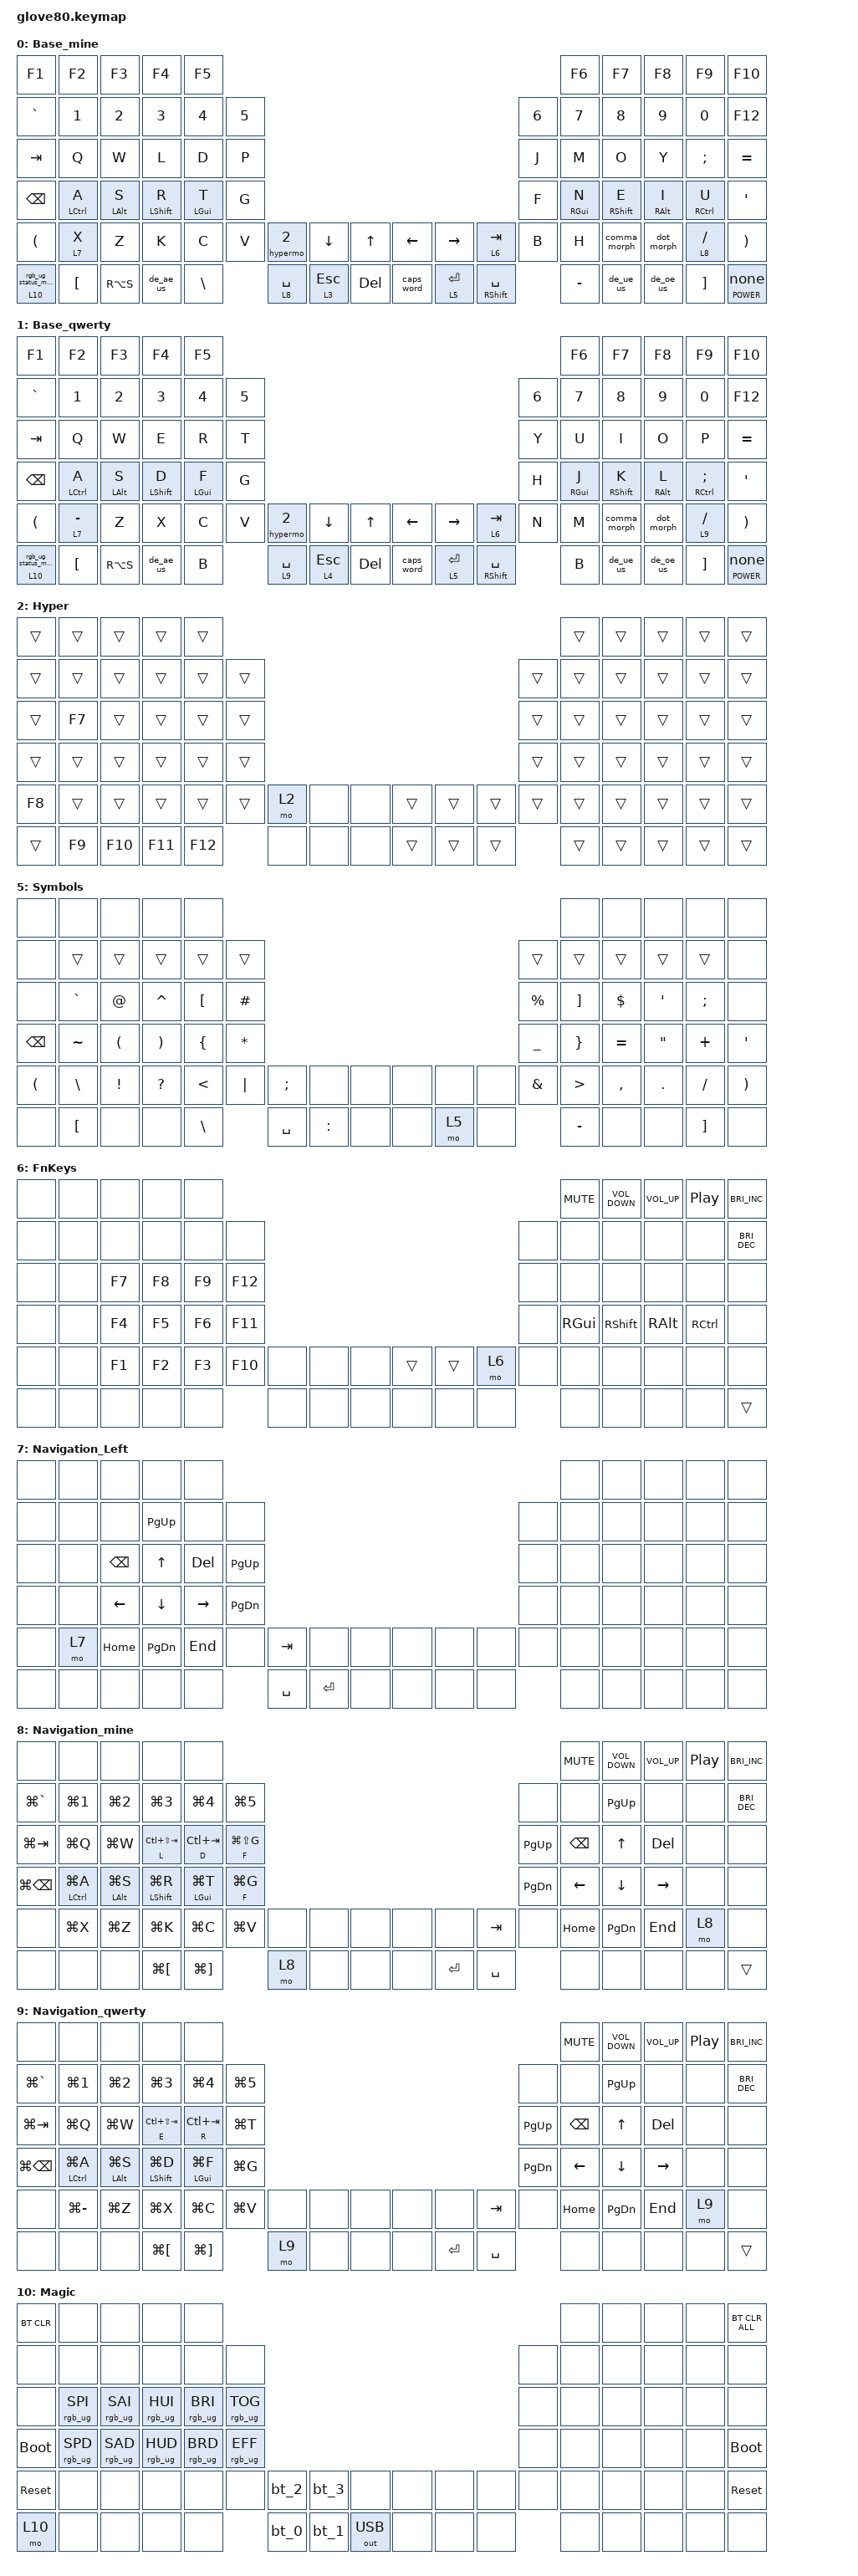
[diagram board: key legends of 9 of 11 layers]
/*
 * Copyright (c) 2020 The ZMK Contributors
 *
 * SPDX-License-Identifier: MIT
 */

#include <behaviors.dtsi>
#include <dt-bindings/zmk/bt.h>
#include <dt-bindings/zmk/keys.h>
#include <dt-bindings/zmk/outputs.h>
#include <dt-bindings/zmk/rgb.h>

&lt {
    quick-tap-ms = <200>;
    flavor = "balanced";
};

&mt {
    flavor = "balanced";
    quick-tap-ms = <200>;
};

&sk {
    quick-release;
    release-after-ms = <500>;
};

&sl {
    ignore-modifiers;
    release-after-ms = <500>;
};

/ {
    behaviors {
        magic: magic {
            compatible = "zmk,behavior-hold-tap";
            label = "MAGIC";
            #binding-cells = <2>;
            flavor = "tap-preferred";
            tapping-term-ms = <200>;
            bindings = <&mo>, <&rgb_ug_status_macro>;
        };

        hml: hml {
            compatible = "zmk,behavior-hold-tap";
            label = "HML";
            bindings = <&kp>, <&kp>;

            #binding-cells = <2>;
            tapping-term-ms = <300>;
            quick-tap-ms = <200>;
            require-prior-idle-ms = <100>;
            flavor = "balanced";
            hold-trigger-key-positions = <5 6 7 8 9 16 17 18 19 20 21 28 29 30 31 32 33 40 41 42 43 44 45 57 58 59 60 61 62 63 73 74 75 76 77 78 79 56 72 55 52 53 54 70 71 69>;
            hold-trigger-on-release;
        };

        hmr: hmr {
            compatible = "zmk,behavior-hold-tap";
            label = "HMR";
            bindings = <&kp>, <&kp>;

            #binding-cells = <2>;
            tapping-term-ms = <300>;
            quick-tap-ms = <200>;
            require-prior-idle-ms = <100>;
            flavor = "balanced";
            hold-trigger-key-positions = <57 73 74 56 72 55 52 53 54 70 71 69 0 1 2 3 4 10 11 12 13 14 15 22 23 24 25 26 27 34 35 36 37 38 39 46 47 48 49 50 51 52 64 65 66 67 68 69 70>;
            hold-trigger-on-release;
        };

        comma_morph: comma_morph {
            compatible = "zmk,behavior-mod-morph";
            label = "COMMA_MORPH";
            bindings = <&kp COMMA>, <&comma_shift>;

            #binding-cells = <0>;
            mods = <(MOD_LSFT|MOD_RSFT)>;
        };

        dot_morph: dot_morph {
            compatible = "zmk,behavior-mod-morph";
            label = "DOT_MORPH";
            bindings = <&kp DOT>, <&dot_shift>;

            #binding-cells = <0>;
            mods = <(MOD_LSFT|MOD_RSFT)>;
        };

        cmdhold: cmdhold {
            compatible = "zmk,behavior-hold-tap";
            label = "CMDHOLD";
            bindings = <&cmdtap>, <&kp>;

            #binding-cells = <2>;
            flavor = "tap-preferred";
            tapping-term-ms = <200>;
        };

        cmdsfthold: cmdsfthold {
            compatible = "zmk,behavior-hold-tap";
            label = "CMDSFTHOLD";
            bindings = <&cmdsfttap>, <&kp>;

            #binding-cells = <2>;
            tapping-term-ms = <200>;
            flavor = "tap-preferred";
        };

        hypermo_kp: hypermo_kp {
            compatible = "zmk,behavior-hold-tap";
            label = "HYPERMO_KP";
            bindings = <&hypermo>, <&kp>;

            #binding-cells = <2>;
            tapping-term-ms = <200>;
            flavor = "balanced";
            quick-tap-ms = <200>;
        };

        hypermo_sk: hypermo_sk {
            compatible = "zmk,behavior-hold-tap";
            label = "HYPERMO_SK";
            bindings = <&hypermo>, <&sk>;

            #binding-cells = <2>;
            tapping-term-ms = <200>;
            flavor = "balanced";
        };

        lpar_lt: lpar_lt {
            compatible = "zmk,behavior-mod-morph";
            label = "LPAR_LT";
            bindings = <&kp LEFT_PARENTHESIS>, <&kp LESS_THAN>;

            #binding-cells = <0>;
            mods = <(MOD_LSFT|MOD_RSFT)>;
        };

        rpar_gt: rpar_gt {
            compatible = "zmk,behavior-mod-morph";
            label = "RPAR_GT";
            bindings = <&kp RIGHT_PARENTHESIS>, <&kp GREATER_THAN>;

            #binding-cells = <0>;
            mods = <(MOD_LSFT|MOD_RSFT)>;
        };

        ltw: ltw {
            compatible = "zmk,behavior-hold-tap";
            label = "LTW";
            bindings = <&mo>, <&kp>;

            #binding-cells = <2>;
            tapping-term-ms = <200>;
            flavor = "balanced";
        };

        htw: htw {
            compatible = "zmk,behavior-hold-tap";
            label = "HTW";
            bindings = <&tap>, <&kp>;

            #binding-cells = <2>;
            tapping-term-ms = <200>;
            flavor = "balanced";
        };

        de_ae_us: de_ae_us {
            compatible = "zmk,behavior-mod-morph";
            label = "DE_AE_US";
            bindings = <&de_ae_lower_us>, <&de_ae_upper_us>;

            #binding-cells = <0>;
            mods = <(MOD_RSFT|MOD_LSFT)>;
        };

        de_ue_us: de_ue_us {
            compatible = "zmk,behavior-mod-morph";
            label = "DE_UE_US";
            bindings = <&de_ue_lower_us>, <&de_ue_upper_us>;

            #binding-cells = <0>;
            mods = <(MOD_RSFT|MOD_LSFT)>;
        };

        de_oe_us: de_oe_us {
            compatible = "zmk,behavior-mod-morph";
            label = "DE_OE_US";
            bindings = <&de_oe_lower_us>, <&de_oe_upper_us>;

            #binding-cells = <0>;
            mods = <(MOD_RSFT|MOD_LSFT)>;
        };

        ht_sk_kp: ht_sk_kp {
            compatible = "zmk,behavior-hold-tap";
            label = "HT_SK_KP";
            bindings = <&sk>, <&kp>;

            #binding-cells = <2>;
            tapping-term-ms = <300>;
            flavor = "hold-preferred";
        };

        long_hold: long_hold {
            compatible = "zmk,behavior-hold-tap";
            label = "LONG_HOLD";
            bindings = <&kp>, <&none>;

            #binding-cells = <2>;
            tapping-term-ms = <2000>;
            flavor = "tap-preferred";
        };

        comma_shift: comma_shift {
            compatible = "zmk,behavior-mod-morph";
            label = "COMMA_SHIFT";
            bindings = <&kp SEMICOLON>, <&kp LESS_THAN>;

            #binding-cells = <0>;
            mods = <(MOD_LCTL|MOD_LGUI|MOD_LALT|MOD_RCTL|MOD_RALT|MOD_RGUI)>;
            keep-mods = <(MOD_LCTL|MOD_LALT|MOD_LGUI|MOD_RCTL|MOD_RALT|MOD_RGUI)>;
        };

        dot_shift: dot_shift {
            compatible = "zmk,behavior-mod-morph";
            label = "DOT_SHIFT";
            bindings = <&kp COLON>, <&kp GREATER_THAN>;

            #binding-cells = <0>;
            mods = <(MOD_LCTL|MOD_LGUI|MOD_LALT|MOD_RCTL|MOD_RALT|MOD_RGUI)>;
            keep-mods = <(MOD_LCTL|MOD_LALT|MOD_LGUI|MOD_RCTL|MOD_RALT|MOD_RGUI)>;
        };
    };

    macros {
        rgb_ug_status_macro: rgb_ug_status_macro_0 {
            label = "RGB_UG_STATUS";
            compatible = "zmk,behavior-macro";
            #binding-cells = <0>;
            bindings = <&rgb_ug RGB_STATUS>;
        };

        bt_0: bt_profile_macro_0 {
            label = "BT_0";
            compatible = "zmk,behavior-macro";
            #binding-cells = <0>;
            bindings = <&out OUT_BLE &bt BT_SEL 0>;
        };

        bt_1: bt_profile_macro_1 {
            label = "BT_1";
            compatible = "zmk,behavior-macro";
            #binding-cells = <0>;
            bindings = <&out OUT_BLE &bt BT_SEL 1>;
        };

        bt_2: bt_profile_macro_2 {
            label = "BT_2";
            compatible = "zmk,behavior-macro";
            #binding-cells = <0>;
            bindings = <&out OUT_BLE &bt BT_SEL 2>;
        };

        bt_3: bt_profile_macro_3 {
            label = "BT_3";
            compatible = "zmk,behavior-macro";
            #binding-cells = <0>;
            bindings = <&out OUT_BLE &bt BT_SEL 3>;
        };

        cmdtap: cmdtap {
            compatible = "zmk,behavior-macro-one-param";
            #binding-cells = <1>;
            bindings =
                <&macro_press>,
                <&kp LGUI>,
                <&macro_tap>,
                <&macro_param_1to1 &kp MACRO_PLACEHOLDER>,
                <&macro_release>,
                <&kp LGUI>;

            label = "CMDTAP";
        };

        cmdsfttap: cmdsfttap {
            compatible = "zmk,behavior-macro-one-param";
            #binding-cells = <1>;
            bindings =
                <&macro_press>,
                <&kp LGUI &kp LSHFT>,
                <&macro_tap>,
                <&macro_param_1to1 &kp MACRO_PLACEHOLDER>,
                <&macro_release>,
                <&kp LSHFT &kp LGUI>;

            label = "CMDSFTTAP";
        };

        hypermo: hypermo {
            compatible = "zmk,behavior-macro-one-param";
            #binding-cells = <1>;
            bindings =
                <&macro_press>,
                <&kp LGUI &kp LALT &kp LCTRL &kp LSHFT &macro_param_1to1 &mo MACRO_PLACEHOLDER>,
                <&macro_pause_for_release>,
                <&macro_release>,
                <&macro_param_1to1 &mo MACRO_PLACEHOLDER &kp LSHFT &kp LCTRL &kp LALT &kp LGUI>;

            label = "HYPERMO";
        };

        tap: tap {
            compatible = "zmk,behavior-macro-one-param";
            #binding-cells = <1>;
            bindings = <&macro_param_1to1 &kp MACRO_PLACEHOLDER>;
            label = "TAP";
        };

        de_ae_lower_us: de_ae_lower_us {
            compatible = "zmk,behavior-macro";
            #binding-cells = <0>;
            bindings = <&kp LA(U) &kp A>;
            label = "DE_AE_LOWER_US";
        };

        de_ae_upper_us: de_ae_upper_us {
            compatible = "zmk,behavior-macro";
            #binding-cells = <0>;
            bindings = <&kp LA(U) &kp LS(A)>;
            label = "DE_AE_UPPER_US";
        };

        de_ue_lower_us: de_ue_lower_us {
            compatible = "zmk,behavior-macro";
            #binding-cells = <0>;
            bindings = <&kp LA(U) &kp U>;
            label = "DE_UE_LOWER_US";
        };

        de_ue_upper_us: de_ue_upper_us {
            compatible = "zmk,behavior-macro";
            #binding-cells = <0>;
            bindings = <&kp LA(U) &kp LS(U)>;
            label = "DE_UE_UPPER_US";
        };

        de_oe_lower_us: de_oe_lower_us {
            compatible = "zmk,behavior-macro";
            #binding-cells = <0>;
            bindings = <&kp LA(U) &kp O>;
            label = "DE_OE_LOWER_US";
        };

        de_oe_upper_us: de_oe_upper_us {
            compatible = "zmk,behavior-macro";
            #binding-cells = <0>;
            bindings = <&kp LA(U) &kp LS(O)>;
            label = "DE_OE_UPPER_US";
        };
    };

    combos {
        compatible = "zmk,combos";

        combo_escape {
            bindings = <&kp ESCAPE>;
            key-positions = <37 36>;
            layers = <0 1>;
            require-prior-idle-ms = <100>;
            timeout-ms = <40>;
        };

        combo_return {
            bindings = <&kp RETURN>;
            key-positions = <42 43>;
            layers = <0 1>;
            timeout-ms = <40>;
            require-prior-idle-ms = <100>;
        };

        combo_minus {
            bindings = <&kp MINUS>;
            key-positions = <30 31>;
            layers = <0 1>;
            timeout-ms = <40>;
        };

        combo_exclamation {
            bindings = <&kp EXCLAMATION>;
            key-positions = <49 48>;
            layers = <0 1>;
            timeout-ms = <40>;
        };

        combo_question {
            bindings = <&kp QUESTION>;
            key-positions = <60 61>;
            layers = <0 1>;
            timeout-ms = <40>;
        };

        combo_equal {
            bindings = <&kp EQUAL>;
            key-positions = <24 25>;
            layers = <0 1>;
            timeout-ms = <40>;
        };
    };

    keymap {
        compatible = "zmk,keymap";

        Base_mine {
            // ---------------------------------------------------------------------------------------------------------------------------------
            // |  F1   |  F2 |  F3 |  F4  |  F5  |                                                               |  F6   |  F7   |  F8  |   F9  |  F10 |
            // |  =    |  1  |  2  |  3   |  4   |  5   |                                                 |  6   |   7   |   8   |  9   |   0   |   -  |
            // |  TAB  |  Q  |  W  |  E   |  R   |  T   |                                                 |  Y   |   U   |   I   |  O   |   P   |   \  |
            // |  ESC  |  A  |  S  |  D   |  F   |  G   |                                                 |  H   |   J   |   K   |  L   |   ;   |   '  |
            // |   `   |  Z  |  X  |  C   |  V   |  B   | LSHFT | LCTRL | LOWER | | LGUI  | RCTRL | RSHFT |  N   |   M   |   ,   |  .   |   /   | PGUP |
            // | MAGIC | HOME| END | LEFT | RIGHT|      | BSPC  | DEL   | LALT  | | RALT  | RET   | SPACE |      |  UP   | DOWN  |  [   |   ]   | PGDN |

            bindings = <
&kp F1                &kp F2            &kp F3       &kp F4        &kp F5                                                                                                                 &kp F6       &kp F7        &kp F8       &kp F9             &kp F10
&kp GRAVE             &kp N1            &kp N2       &kp N3        &kp N4         &kp N5                                                                                          &kp N6  &kp N7       &kp N8        &kp N9       &kp N0             &kp F12
&kp TAB               &kp Q             &kp W        &kp L         &kp D          &kp P                                                                                           &kp J   &kp M        &kp O         &kp Y        &kp SEMICOLON      &kp EQUAL
&kp BACKSPACE         &hml LCTRL A      &hml LALT S  &hml LSHFT R  &hml LGUI T    &kp G                                                                                           &kp F   &hmr RGUI N  &hmr RSHFT E  &hmr RALT I  &hmr RCTRL U       &kp SINGLE_QUOTE
&kp LEFT_PARENTHESIS  &lt 7 X           &kp Z        &kp K         &kp C          &kp V   &hypermo 2   &kp DOWN      &kp UP      &kp LEFT    &kp RIGHT     &lt 6 TAB              &kp B   &kp H        &comma_morph  &dot_morph   &lt 8 SLASH        &kp RIGHT_PARENTHESIS
&magic 10 0           &kp LEFT_BRACKET  &kp RA(S)    &de_ae_us     &kp BACKSLASH          &lt 8 SPACE  &lt 3 ESCAPE  &kp DELETE  &caps_word  &lt 5 RETURN  &ht_sk_kp RSHFT SPACE          &kp MINUS    &de_ue_us     &de_oe_us    &kp RIGHT_BRACKET  &long_hold C_POWER 0
            >;
        };

        Base_qwerty {
            bindings = <
&kp F1                &kp F2            &kp F3       &kp F4        &kp F5                                                                                                               &kp F6       &kp F7        &kp F8       &kp F9                &kp F10
&kp GRAVE             &kp N1            &kp N2       &kp N3        &kp N4       &kp N5                                                                                          &kp N6  &kp N7       &kp N8        &kp N9       &kp N0                &kp F12
&kp TAB               &kp Q             &kp W        &kp E         &kp R        &kp T                                                                                           &kp Y   &kp U        &kp I         &kp O        &kp P                 &kp EQUAL
&kp BACKSPACE         &hml LCTRL A      &hml LALT S  &hml LSHFT D  &hml LGUI F  &kp G                                                                                           &kp H   &hmr RGUI J  &hmr RSHFT K  &hmr RALT L  &hmr RCTRL SEMICOLON  &kp SINGLE_QUOTE
&kp LEFT_PARENTHESIS  &lt 7 MINUS       &kp Z        &kp X         &kp C        &kp V   &hypermo 2   &kp DOWN      &kp UP      &kp LEFT    &kp RIGHT     &lt 6 TAB              &kp N   &kp M        &comma_morph  &dot_morph   &lt 9 SLASH           &kp RIGHT_PARENTHESIS
&magic 10 0           &kp LEFT_BRACKET  &kp RA(S)    &de_ae_us     &kp B                &lt 9 SPACE  &lt 4 ESCAPE  &kp DELETE  &caps_word  &lt 5 RETURN  &ht_sk_kp RSHFT SPACE          &kp B        &de_ue_us     &de_oe_us    &kp RIGHT_BRACKET     &long_hold C_POWER 0
            >;
        };

        Hyper {
            bindings = <
&trans  &trans  &trans   &trans   &trans                                                                &trans  &trans  &trans  &trans  &trans
&trans  &trans  &trans   &trans   &trans   &trans                                               &trans  &trans  &trans  &trans  &trans  &trans
&trans  &kp F7  &trans   &trans   &trans   &trans                                               &trans  &trans  &trans  &trans  &trans  &trans
&trans  &trans  &trans   &trans   &trans   &trans                                               &trans  &trans  &trans  &trans  &trans  &trans
&kp F8  &trans  &trans   &trans   &trans   &trans  &mo 2  &none  &none  &trans  &trans  &trans  &trans  &trans  &trans  &trans  &trans  &trans
&trans  &kp F9  &kp F10  &kp F11  &kp F12          &none  &none  &none  &trans  &trans  &trans          &trans  &trans  &trans  &trans  &trans
            >;
        };

        NumMeh_mine {
            bindings = <
&none                  &none                    &none                   &none                    &none                                                                                                              &none   &none      &none    &none              &none
&kp LC(LA(LG(GRAVE)))  &kp LC(LA(LG(N1)))       &kp LC(LA(LG(N2)))      &kp LC(LA(LG(N3)))       &kp LC(LA(LG(N4)))      &kp LC(LA(LG(N5)))                                                          &none          &none   &none      &none    &none              &none
&kp LC(LA(LG(TAB)))    &kp LC(LA(LG(F7)))       &kp LC(LA(LG(W)))       &kp LC(LA(LG(L)))        &kp LC(LA(LG(D)))       &kp LC(LA(LG(P)))                                                           &kp BACKSPACE  &kp N7  &kp N8     &kp N9   &none              &none
&kp BACKSPACE          &mt LCTRL LC(LA(LG(A)))  &mt LALT LC(LA(LG(S)))  &mt LSHFT LC(LA(LG(R)))  &mt LGUI LC(LA(LG(T)))  &kp LC(LA(LG(G)))                                                           &kp KP_MINUS   &kp N4  &kp N5     &kp N6   &kp KP_PLUS        &none
&kp LEFT_PARENTHESIS   &kp LC(LA(LG(X)))        &kp LC(LA(LG(Z)))       &kp LC(LA(LG(K)))        &kp LC(LA(LG(C)))       &kp LC(LA(LG(V)))   &none  &none  &none  &trans          &trans     &trans  &kp KP_DIVIDE  &kp N1  &kp N2     &kp N3   &kp KP_MULTIPLY    &kp RIGHT_PARENTHESIS
&none                  &kp LEFT_BRACKET         &kp LC(LA(LG(F10)))     &kp LC(LA(LG(F11)))      &kp LC(LA(LG(F12)))                         &none  &mo 3  &none  &kp RA(RS(N2))  &kp COLON  &kp N0                 &kp N0  &kp COMMA  &kp DOT  &kp RIGHT_BRACKET  &none
            >;
        };

        NumMeh_qwerty {
            bindings = <
&none                  &none                    &none                   &none                    &none                                                                                                              &none   &none      &none    &none              &none
&kp LC(LA(LG(GRAVE)))  &kp LC(LA(LG(N1)))       &kp LC(LA(LG(N2)))      &kp LC(LA(LG(N3)))       &kp LC(LA(LG(N4)))      &kp LC(LA(LG(N5)))                                                          &none          &none   &none      &none    &none              &none
&kp LC(LA(LG(TAB)))    &kp LC(LA(LG(F7)))       &kp LC(LA(LG(W)))       &kp LC(LA(LG(E)))        &kp LC(LA(LG(R)))       &kp LC(LA(LG(T)))                                                           &kp BACKSPACE  &kp N7  &kp N8     &kp N9   &none              &none
&kp BACKSPACE          &mt LCTRL LC(LA(LG(A)))  &mt LALT LC(LA(LG(S)))  &mt LSHFT LC(LA(LG(D)))  &mt LGUI LC(LA(LG(F)))  &kp LC(LA(LG(G)))                                                           &kp KP_MINUS   &kp N4  &kp N5     &kp N6   &kp KP_PLUS        &none
&kp LEFT_PARENTHESIS   &kp LC(LA(LG(MINUS)))    &kp LC(LA(LG(Z)))       &kp LC(LA(LG(X)))        &kp LC(LA(LG(C)))       &kp LC(LA(LG(V)))   &none  &none  &none  &trans          &trans     &trans  &kp KP_DIVIDE  &kp N1  &kp N2     &kp N3   &kp KP_MULTIPLY    &kp RIGHT_PARENTHESIS
&none                  &kp LEFT_BRACKET         &kp LC(LA(LG(F10)))     &kp LC(LA(LG(F11)))      &kp LC(LA(LG(F12)))                         &none  &mo 4  &none  &kp RA(RS(N2))  &kp COLON  &kp N0                 &kp N0  &kp COMMA  &kp DOT  &kp RIGHT_BRACKET  &none
            >;
        };

        Symbols {
            bindings = <
&none                 &none             &none                 &none                  &none                                                                                                 &none              &none       &none              &none              &none
&none                 &trans            &trans                &trans                 &trans            &trans                                                              &trans          &trans             &trans      &trans             &trans             &none
&none                 &kp GRAVE         &kp AT_SIGN           &kp CARET              &kp LEFT_BRACKET  &kp HASH                                                            &kp PERCENT     &kp RIGHT_BRACKET  &kp DOLLAR  &kp SINGLE_QUOTE   &kp SEMICOLON      &none
&kp BACKSPACE         &kp TILDE         &kp LEFT_PARENTHESIS  &kp RIGHT_PARENTHESIS  &kp LEFT_BRACE    &kp ASTERISK                                                        &kp UNDERSCORE  &kp RIGHT_BRACE    &kp EQUAL   &kp DOUBLE_QUOTES  &kp PLUS           &kp SINGLE_QUOTE
&kp LEFT_PARENTHESIS  &kp BACKSLASH     &kp EXCLAMATION       &kp QUESTION           &kp LESS_THAN     &kp PIPE      &kp SEMICOLON  &none      &none  &none  &none  &none  &kp AMPERSAND   &kp GREATER_THAN   &kp COMMA   &kp DOT            &kp SLASH          &kp RIGHT_PARENTHESIS
&none                 &kp LEFT_BRACKET  &none                 &none                  &kp BACKSLASH                   &kp SPACE      &kp COLON  &none  &none  &mo 5  &none                  &kp MINUS          &none       &none              &kp RIGHT_BRACKET  &none
            >;
        };

        FnKeys {
            bindings = <
&none  &none  &none   &none   &none                                                               &kp C_MUTE  &kp C_VOLUME_DOWN  &kp C_VOLUME_UP  &kp C_PLAY_PAUSE  &kp C_BRIGHTNESS_INC
&none  &none  &none   &none   &none   &none                                                &none  &none       &none              &none            &none             &kp C_BRIGHTNESS_DEC
&none  &none  &kp F7  &kp F8  &kp F9  &kp F12                                              &none  &none       &none              &none            &none             &none
&none  &none  &kp F4  &kp F5  &kp F6  &kp F11                                              &none  &kp RGUI    &kp RSHFT          &kp RALT         &kp RCTRL         &none
&none  &none  &kp F1  &kp F2  &kp F3  &kp F10  &none  &none  &none  &trans  &trans  &mo 6  &none  &none       &none              &none            &none             &none
&none  &none  &none   &none   &none            &none  &none  &none  &none   &none   &none         &none       &none              &none            &none             &trans
            >;
        };

        Navigation_Left {
            bindings = <
&none  &none  &none     &none          &none                                                                            &none  &none  &none  &none  &none
&none  &none  &none     &kp PAGE_UP    &none      &none                                                          &none  &none  &none  &none  &none  &none
&none  &none  &kp BSPC  &kp UP         &kp DEL    &kp PAGE_UP                                                    &none  &none  &none  &none  &none  &none
&none  &none  &kp LEFT  &kp DOWN       &kp RIGHT  &kp PAGE_DOWN                                                  &none  &none  &none  &none  &none  &none
&none  &mo 7  &kp HOME  &kp PAGE_DOWN  &kp END    &none          &kp TAB    &none    &none  &none  &none  &none  &none  &none  &none  &none  &none  &none
&none  &none  &none     &none          &none                     &kp SPACE  &kp RET  &none  &none  &none  &none         &none  &none  &none  &none  &none
            >;
        };

        Navigation_mine {
            bindings = <
&none              &none            &none           &none                   &none                                                                                                             &kp C_MUTE  &kp C_VOLUME_DOWN  &kp C_VOLUME_UP  &kp C_PLAY_PAUSE  &kp C_BRIGHTNESS_INC
&kp LG(GRAVE)      &kp LG(N1)       &kp LG(N2)      &kp LG(N3)              &kp LG(N4)             &kp LG(N5)                                                                  &none          &none       &kp PAGE_UP        &none            &none             &kp C_BRIGHTNESS_DEC
&kp LG(TAB)        &kp LG(Q)        &kp LG(W)       &cmdhold L LC(LS(TAB))  &cmdhold D LC(TAB)     &cmdsfthold F LG(LS(G))                                                     &kp PAGE_UP    &kp BSPC    &kp UP             &kp DELETE       &none             &none
&kp LG(BACKSPACE)  &mt LCTRL LG(A)  &mt LALT LG(S)  &mt LSHFT LG(R)         &mt LGUI LG(T)         &cmdhold F LG(G)                                                            &kp PAGE_DOWN  &kp LEFT    &kp DOWN           &kp RIGHT        &none             &none
&none              &kp LG(X)        &kp LG(Z)       &kp LG(K)               &kp LG(C)              &kp LG(V)                &none  &none  &none  &none  &none       &kp TAB    &none          &kp HOME    &kp PAGE_DOWN      &kp END          &mo 8             &none
&none              &none            &none           &kp LG(LEFT_BRACKET)    &kp LG(RIGHT_BRACKET)                           &mo 8  &none  &none  &none  &kp RETURN  &kp SPACE                 &none       &none              &none            &none             &trans
            >;
        };

        Navigation_qwerty {
            bindings = <
&none              &none            &none           &none                   &none                                                                                                &kp C_MUTE  &kp C_VOLUME_DOWN  &kp C_VOLUME_UP  &kp C_PLAY_PAUSE  &kp C_BRIGHTNESS_INC
&kp LG(GRAVE)      &kp LG(N1)       &kp LG(N2)      &kp LG(N3)              &kp LG(N4)             &kp LG(N5)                                                     &none          &none       &kp PAGE_UP        &none            &none             &kp C_BRIGHTNESS_DEC
&kp LG(TAB)        &kp LG(Q)        &kp LG(W)       &cmdhold E LC(LS(TAB))  &cmdhold R LC(TAB)     &kp LG(T)                                                      &kp PAGE_UP    &kp BSPC    &kp UP             &kp DELETE       &none             &none
&kp LG(BACKSPACE)  &mt LCTRL LG(A)  &mt LALT LG(S)  &mt LSHFT LG(D)         &mt LGUI LG(F)         &kp LG(G)                                                      &kp PAGE_DOWN  &kp LEFT    &kp DOWN           &kp RIGHT        &none             &none
&none              &kp LG(MINUS)    &kp LG(Z)       &kp LG(X)               &kp LG(C)              &kp LG(V)   &none  &none  &none  &none  &none       &kp TAB    &none          &kp HOME    &kp PAGE_DOWN      &kp END          &mo 9             &none
&none              &none            &none           &kp LG(LEFT_BRACKET)    &kp LG(RIGHT_BRACKET)              &mo 9  &none  &none  &none  &kp RETURN  &kp SPACE                 &none       &none              &none            &none             &trans
            >;
        };

        Magic {
            bindings = <
&bt BT_CLR   &none            &none            &none            &none                                                                                     &none  &none  &none  &none  &bt BT_CLR_ALL
&none        &none            &none            &none            &none            &none                                                             &none  &none  &none  &none  &none  &none
&none        &rgb_ug RGB_SPI  &rgb_ug RGB_SAI  &rgb_ug RGB_HUI  &rgb_ug RGB_BRI  &rgb_ug RGB_TOG                                                   &none  &none  &none  &none  &none  &none
&bootloader  &rgb_ug RGB_SPD  &rgb_ug RGB_SAD  &rgb_ug RGB_HUD  &rgb_ug RGB_BRD  &rgb_ug RGB_EFF                                                   &none  &none  &none  &none  &none  &bootloader
&sys_reset   &none            &none            &none            &none            &none            &bt_2  &bt_3  &none         &none  &none  &none  &none  &none  &none  &none  &none  &sys_reset
&mo 10       &none            &none            &none            &none                             &bt_0  &bt_1  &out OUT_USB  &none  &none  &none         &none  &none  &none  &none  &none
            >;
        };
    };
};
